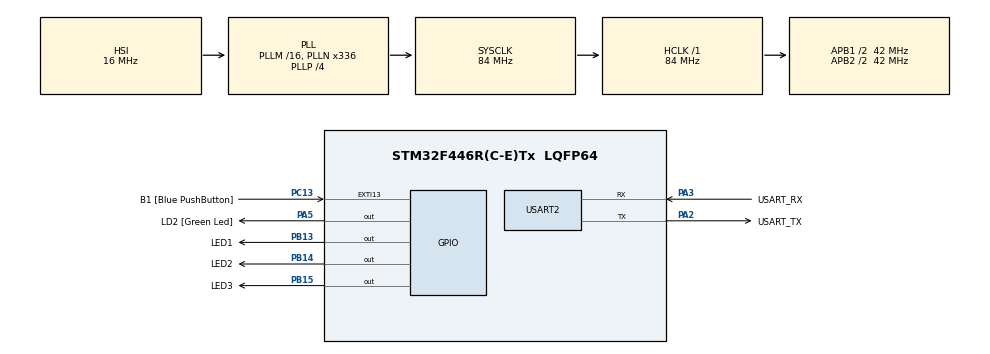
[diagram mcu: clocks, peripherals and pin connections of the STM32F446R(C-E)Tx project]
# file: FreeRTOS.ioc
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Dma.Request0=USART2_RX
Dma.Request1=USART2_TX
Dma.USART2_RX.0.Direction=DMA_PERIPH_TO_MEMORY
Dma.USART2_RX.0.FIFOMode=DMA_FIFOMODE_DISABLE
Dma.USART2_RX.0.Instance=DMA1_Stream5
Dma.USART2_RX.0.MemDataAlignment=DMA_MDATAALIGN_BYTE
Dma.USART2_RX.0.MemInc=DMA_MINC_ENABLE
Dma.USART2_RX.0.Mode=DMA_CIRCULAR
Dma.USART2_RX.0.PeriphDataAlignment=DMA_PDATAALIGN_BYTE
Dma.USART2_RX.0.PeriphInc=DMA_PINC_DISABLE
Dma.USART2_RX.0.Priority=DMA_PRIORITY_LOW
Dma.USART2_TX.1.Direction=DMA_MEMORY_TO_PERIPH
Dma.USART2_TX.1.FIFOMode=DMA_FIFOMODE_DISABLE
Dma.USART2_TX.1.Instance=DMA1_Stream6
Dma.USART2_TX.1.MemDataAlignment=DMA_MDATAALIGN_BYTE
Dma.USART2_TX.1.MemInc=DMA_MINC_ENABLE
Dma.USART2_TX.1.Mode=DMA_CIRCULAR
Dma.USART2_TX.1.PeriphDataAlignment=DMA_PDATAALIGN_BYTE
Dma.USART2_TX.1.PeriphInc=DMA_PINC_DISABLE
Dma.USART2_TX.1.Priority=DMA_PRIORITY_LOW
FREERTOS.Tasks01=defaultTask,0,128,StartDefaultTask,Default
Mcu.Family=STM32F4
Mcu.Name=STM32F446R(C-E)Tx
Mcu.Package=LQFP64
NVIC.DMA1_Stream5_IRQn=true\:5\:0\:false\:false\:true\:true
NVIC.DMA1_Stream6_IRQn=true\:5\:0\:false\:false\:true\:true
NVIC.EXTI15_10_IRQn=true\:5\:0\:false\:false\:true\:true
NVIC.PriorityGroup=NVIC_PRIORITYGROUP_4
NVIC.TIM1_UP_TIM10_IRQn=true\:0\:0\:false\:false\:true\:false
NVIC.TimeBase=TIM1_UP_TIM10_IRQn
NVIC.TimeBaseIP=TIM1
NVIC.USART2_IRQn=true\:5\:0\:false\:false\:true\:true
PA13.GPIO_Label=TMS
PA13.Signal=SYS_JTMS-SWDIO
PA14.GPIO_Label=TCK
PA14.Signal=SYS_JTCK-SWCLK
PA2.GPIO_Label=USART_TX
PA2.Mode=Asynchronous
PA2.Signal=USART2_TX
PA3.GPIO_Label=USART_RX
PA3.Mode=Asynchronous
PA3.Signal=USART2_RX
PA5.GPIO_Label=LD2 [Green Led]
PA5.Signal=GPIO_Output
PB13.GPIO_Label=LED1
PB13.Signal=GPIO_Output
PB14.GPIO_Label=LED2
PB14.Signal=GPIO_Output
PB15.GPIO_Label=LED3
PB15.Signal=GPIO_Output
PB3.GPIO_Label=SWO
PB3.Signal=SYS_JTDO-SWO
PC13.GPIO_Label=B1 [Blue PushButton]
PC13.GPIO_ModeDefaultEXTI=GPIO_MODE_IT_RISING
PC13.Signal=GPXTI13
PC14-OSC32_IN.Signal=RCC_OSC32_IN
PC15-OSC32_OUT.Signal=RCC_OSC32_OUT
PH0-OSC_IN.Signal=RCC_OSC_IN
PH1-OSC_OUT.Signal=RCC_OSC_OUT
ProjectManager.HeapSize=0x200
ProjectManager.StackSize=0x400
ProjectManager.TargetToolchain=TrueSTUDIO
RCC.AHBFreq_Value=84000000
RCC.APB1CLKDivider=RCC_HCLK_DIV2
RCC.APB1Freq_Value=42000000
RCC.APB1TimFreq_Value=84000000
RCC.APB2CLKDivider=RCC_HCLK_DIV2
RCC.APB2Freq_Value=42000000
RCC.APB2TimFreq_Value=84000000
RCC.CortexFreq_Value=84000000
RCC.FLatency-AdvancedSettings=FLASH_LATENCY_2
RCC.HCLKFreq_Value=84000000
RCC.HSE_VALUE=8000000
RCC.HSI_VALUE=16000000
RCC.LSE_VALUE=32768
RCC.PLLN=336
RCC.PLLP=RCC_PLLP_DIV4
RCC.SYSCLKFreq_VALUE=84000000
RCC.SYSCLKSource=RCC_SYSCLKSOURCE_PLLCLK
RCC.USBFreq_Value=168000000
RCC.VCOOutputFreq_Value=336000000
VP_FREERTOS_VS_ENABLE.Mode=Enabled
VP_SYS_VS_tim1.Mode=TIM1
board=NUCLEO-F446RE

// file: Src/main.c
/**
  ******************************************************************************
  * File Name          : main.c
  * Description        : Main program body
  ******************************************************************************
  *
  * COPYRIGHT(c) 2016 STMicroelectronics
  *
  * Redistribution and use in source and binary forms, with or without modification,
  * are permitted provided that the following conditions are met:
  *   1. Redistributions of source code must retain the above copyright notice,
  *      this list of conditions and the following disclaimer.
  *   2. Redistributions in binary form must reproduce the above copyright notice,
  *      this list of conditions and the following disclaimer in the documentation
  *      and/or other materials provided with the distribution.
  *   3. Neither the name of STMicroelectronics nor the names of its contributors
  *      may be used to endorse or promote products derived from this software
  *      without specific prior written permission.
  *
  * THIS SOFTWARE IS PROVIDED BY THE COPYRIGHT HOLDERS AND CONTRIBUTORS "AS IS"
  * AND ANY EXPRESS OR IMPLIED WARRANTIES, INCLUDING, BUT NOT LIMITED TO, THE
  * IMPLIED WARRANTIES OF MERCHANTABILITY AND FITNESS FOR A PARTICULAR PURPOSE ARE
  * DISCLAIMED. IN NO EVENT SHALL THE COPYRIGHT HOLDER OR CONTRIBUTORS BE LIABLE
  * FOR ANY DIRECT, INDIRECT, INCIDENTAL, SPECIAL, EXEMPLARY, OR CONSEQUENTIAL
  * DAMAGES (INCLUDING, BUT NOT LIMITED TO, PROCUREMENT OF SUBSTITUTE GOODS OR
  * SERVICES; LOSS OF USE, DATA, OR PROFITS; OR BUSINESS INTERRUPTION) HOWEVER
  * CAUSED AND ON ANY THEORY OF LIABILITY, WHETHER IN CONTRACT, STRICT LIABILITY,
  * OR TORT (INCLUDING NEGLIGENCE OR OTHERWISE) ARISING IN ANY WAY OUT OF THE USE
  * OF THIS SOFTWARE, EVEN IF ADVISED OF THE POSSIBILITY OF SUCH DAMAGE.
  *
  ******************************************************************************
  */
#include "stm32f4xx_hal.h"
#include "cmsis_os.h"

UART_HandleTypeDef huart2;
DMA_HandleTypeDef hdma_usart2_rx;
DMA_HandleTypeDef hdma_usart2_tx;
osThreadId defaultTaskHandle;

/* USER CODE BEGIN PV */
osThreadId defaultTaskHandle;
osThreadId blinkTaskHandle;
osSemaphoreId semHandle;
///* USER CODE END PV */

void SystemClock_Config(void);
void Error_Handler(void);
static void MX_GPIO_Init(void);
static void MX_DMA_Init(void);
static void MX_USART2_UART_Init(void);
void StartDefaultTask(void const * argument);

/* USER CODE BEGIN PFP */
/* Private function prototypes -----------------------------------------------*/
void BlinkTask(void const *argument);
/* USER CODE END PFP */

int main(void)
{

  /* MCU Configuration----------------------------------------------------------*/

  /* Reset of all peripherals, Initializes the Flash interface and the Systick. */
  HAL_Init();

  /* Configure the system clock */
  SystemClock_Config();

  /* Initialize all configured peripherals */
  MX_GPIO_Init();
  MX_DMA_Init();
  MX_USART2_UART_Init();

  /* USER CODE BEGIN 2 */

  /* Create the threads and semaphore */
//  osThreadDef(defaultTask, StartDefaultTask, osPriorityNormal, 0, 128);
//  defaultTaskHandle = osThreadCreate(osThread(defaultTask), NULL);
  osThreadDef(blinkTask, BlinkTask, osPriorityNormal, 0, 128);
  blinkTaskHandle = osThreadCreate(osThread(blinkTask), NULL);
  osSemaphoreDef(sem);
  semHandle = osSemaphoreCreate(osSemaphore(sem), 1);
  osSemaphoreWait(semHandle, osWaitForever);

  /* USER CODE END 2 */

  /* Create the thread(s) */
  /* definition and creation of defaultTask */
  osThreadDef(defaultTask, StartDefaultTask, osPriorityNormal, 0, 128);
  defaultTaskHandle = osThreadCreate(osThread(defaultTask), NULL);

  /* Start scheduler */
  osKernelStart();

  /* We should never get here as control is now taken by the scheduler */

  /* Infinite loop */
  while (1)
  {

  }

}

/** System Clock Configuration
*/
void SystemClock_Config(void)
{

  RCC_OscInitTypeDef RCC_OscInitStruct;
  RCC_ClkInitTypeDef RCC_ClkInitStruct;

  __HAL_RCC_PWR_CLK_ENABLE();

  __HAL_PWR_VOLTAGESCALING_CONFIG(PWR_REGULATOR_VOLTAGE_SCALE3);

  RCC_OscInitStruct.OscillatorType = RCC_OSCILLATORTYPE_HSI;
  RCC_OscInitStruct.HSIState = RCC_HSI_ON;
  RCC_OscInitStruct.HSICalibrationValue = 16;
  RCC_OscInitStruct.PLL.PLLState = RCC_PLL_ON;
  RCC_OscInitStruct.PLL.PLLSource = RCC_PLLSOURCE_HSI;
  RCC_OscInitStruct.PLL.PLLM = 16;
  RCC_OscInitStruct.PLL.PLLN = 336;
  RCC_OscInitStruct.PLL.PLLP = RCC_PLLP_DIV4;
  RCC_OscInitStruct.PLL.PLLQ = 2;
  RCC_OscInitStruct.PLL.PLLR = 2;
  if (HAL_RCC_OscConfig(&RCC_OscInitStruct) != HAL_OK)
  {
    Error_Handler();
  }

  RCC_ClkInitStruct.ClockType = RCC_CLOCKTYPE_HCLK|RCC_CLOCKTYPE_SYSCLK
                              |RCC_CLOCKTYPE_PCLK1|RCC_CLOCKTYPE_PCLK2;
  RCC_ClkInitStruct.SYSCLKSource = RCC_SYSCLKSOURCE_PLLCLK;
  RCC_ClkInitStruct.AHBCLKDivider = RCC_SYSCLK_DIV1;
  RCC_ClkInitStruct.APB1CLKDivider = RCC_HCLK_DIV2;
  RCC_ClkInitStruct.APB2CLKDivider = RCC_HCLK_DIV2;
  if (HAL_RCC_ClockConfig(&RCC_ClkInitStruct, FLASH_LATENCY_2) != HAL_OK)
  {
    Error_Handler();
  }

  HAL_SYSTICK_Config(HAL_RCC_GetHCLKFreq()/1000);

  HAL_SYSTICK_CLKSourceConfig(SYSTICK_CLKSOURCE_HCLK);

  /* SysTick_IRQn interrupt configuration */
  HAL_NVIC_SetPriority(SysTick_IRQn, 15, 0);
}

/* USART2 init function */
static void MX_USART2_UART_Init(void)
{

  huart2.Instance = USART2;
  huart2.Init.BaudRate = 115200;
  huart2.Init.WordLength = UART_WORDLENGTH_8B;
  huart2.Init.StopBits = UART_STOPBITS_1;
  huart2.Init.Parity = UART_PARITY_NONE;
  huart2.Init.Mode = UART_MODE_TX_RX;
  huart2.Init.HwFlowCtl = UART_HWCONTROL_NONE;
  huart2.Init.OverSampling = UART_OVERSAMPLING_16;
  if (HAL_UART_Init(&huart2) != HAL_OK)
  {
    Error_Handler();
  }

}

static void MX_DMA_Init(void)
{
  /* DMA controller clock enable */
  __HAL_RCC_DMA1_CLK_ENABLE();

  /* DMA interrupt init */
  /* DMA1_Stream5_IRQn interrupt configuration */
  HAL_NVIC_SetPriority(DMA1_Stream5_IRQn, 5, 0);
  HAL_NVIC_EnableIRQ(DMA1_Stream5_IRQn);
  /* DMA1_Stream6_IRQn interrupt configuration */
  HAL_NVIC_SetPriority(DMA1_Stream6_IRQn, 5, 0);
  HAL_NVIC_EnableIRQ(DMA1_Stream6_IRQn);

}

/** Configure pins as
        * Analog
        * Input
        * Output
        * EVENT_OUT
        * EXTI
*/
static void MX_GPIO_Init(void)
{

  GPIO_InitTypeDef GPIO_InitStruct;

  /* GPIO Ports Clock Enable */
  __HAL_RCC_GPIOC_CLK_ENABLE();
  __HAL_RCC_GPIOH_CLK_ENABLE();
  __HAL_RCC_GPIOA_CLK_ENABLE();
  __HAL_RCC_GPIOB_CLK_ENABLE();

  /*Configure GPIO pin : B1_Pin */
  GPIO_InitStruct.Pin = B1_Pin;
  GPIO_InitStruct.Mode = GPIO_MODE_IT_RISING;
  GPIO_InitStruct.Pull = GPIO_NOPULL;
  HAL_GPIO_Init(B1_GPIO_Port, &GPIO_InitStruct);

  /*Configure GPIO pin : LD2_Pin */
  GPIO_InitStruct.Pin = LD2_Pin;
  GPIO_InitStruct.Mode = GPIO_MODE_OUTPUT_PP;
  GPIO_InitStruct.Pull = GPIO_NOPULL;
  GPIO_InitStruct.Speed = GPIO_SPEED_FREQ_LOW;
  HAL_GPIO_Init(LD2_GPIO_Port, &GPIO_InitStruct);

  /*Configure GPIO pins : LED1_Pin LED2_Pin LED3_Pin */
  GPIO_InitStruct.Pin = LED1_Pin|LED2_Pin|LED3_Pin;
  GPIO_InitStruct.Mode = GPIO_MODE_OUTPUT_PP;
  GPIO_InitStruct.Pull = GPIO_NOPULL;
  GPIO_InitStruct.Speed = GPIO_SPEED_FREQ_LOW;
  HAL_GPIO_Init(GPIOB, &GPIO_InitStruct);

  /*Configure GPIO pin Output Level */
  HAL_GPIO_WritePin(LD2_GPIO_Port, LD2_Pin, GPIO_PIN_RESET);

  /*Configure GPIO pin Output Level */
  HAL_GPIO_WritePin(GPIOB, LED1_Pin|LED2_Pin|LED3_Pin, GPIO_PIN_RESET);

  /* EXTI interrupt init*/
  HAL_NVIC_SetPriority(EXTI15_10_IRQn, 5, 0);
  HAL_NVIC_EnableIRQ(EXTI15_10_IRQn);

}

///* USER CODE BEGIN 4 */
void BlinkTask(void const *argument)
{
	if(osSemaphoreWait(semHandle, osWaitForever) == osOK) {
		while(1) {
			HAL_GPIO_TogglePin(LD2_GPIO_Port, LD2_Pin);
			osDelay(500);
		}
	}
}
///* USER CODE END 4 */
//
///* StartDefaultTask function */
void StartDefaultTask(void const * argument)
{

  /* USER CODE BEGIN 5 */
  /* Infinite loop */
	 while(1) {
		  if(!HAL_GPIO_ReadPin(B1_GPIO_Port, B1_Pin)) {
			  osSemaphoreRelease(semHandle);
			  osThreadTerminate(NULL);
		  	  }

		  }
  /* USER CODE END 5 */
}

void HAL_TIM_PeriodElapsedCallback(TIM_HandleTypeDef *htim)
{
  if (htim->Instance == TIM1) {
    HAL_IncTick();
  }
}

void Error_Handler(void)
{
  while(1)
  {
  }
}

/************************ (C) COPYRIGHT STMicroelectronics *****END OF FILE****/
